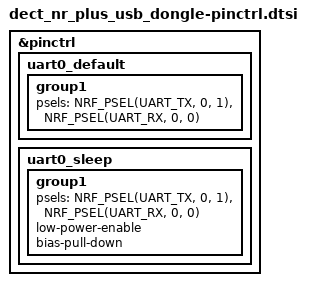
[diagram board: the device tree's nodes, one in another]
/*
 * Copyright (c) 2026 Norik Systems
 *
 * SPDX-License-Identifier: Apache-2.0
 */

&pinctrl {
	uart0_default: uart0_default {
		group1 {
			psels = <NRF_PSEL(UART_TX, 0, 1)>,
				<NRF_PSEL(UART_RX, 0, 0)>;
		};
	};

	uart0_sleep: uart0_sleep {
		group1 {
			psels = <NRF_PSEL(UART_TX, 0, 1)>,
				<NRF_PSEL(UART_RX, 0, 0)>;
			low-power-enable;
			bias-pull-down;
		};
	};
};
